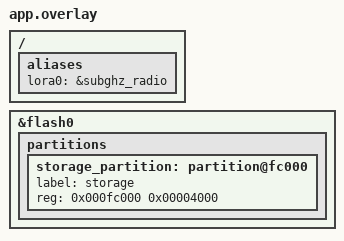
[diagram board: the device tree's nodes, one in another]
/ {
	aliases {
		lora0 = &subghz_radio;
	};
};

&flash0 {
    partitions {
        storage_partition: partition@fc000 {
            label = "storage";
            reg = <0x000fc000 0x00004000>; /* adjust size as needed */
        };
    };
};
